VERSION ""

NS_ :

BS_:

BU_: XXX

BO_ 85 CID_RGHIGZ: 8 XXX
 SG_ sig_erymgc : 40|1@1+ (1,0) [0|1] "" XXX
 SG_ sig_tabrsm : 56|8@1+ (1,0) [0|255] "" XXX

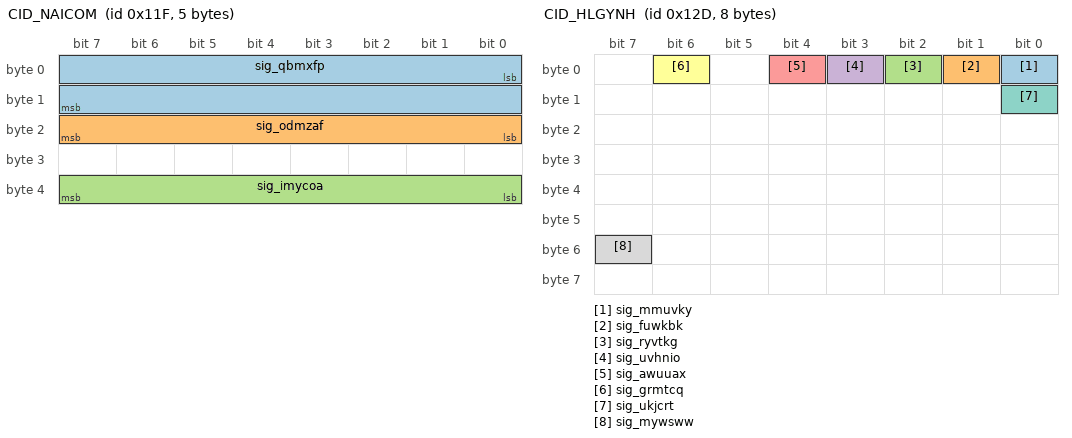
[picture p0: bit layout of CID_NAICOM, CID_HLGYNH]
BO_ 287 CID_NAICOM: 5 XXX
 SG_ sig_qbmxfp : 0|16@1- (0.1,0) [-450|450] "" XXX
 SG_ sig_odmzaf : 16|8@1+ (4,0) [0|1020] "" XXX
 SG_ sig_imycoa : 32|8@1+ (1,0) [0|255] "" XXX

BO_ 289 CID_RRNNRT: 8 XXX
 SG_ sig_yvbsvs : 0|12@1+ (1,0) [0|255] "" XXX

BO_ 301 CID_HLGYNH: 8 XXX
 SG_ sig_mmuvky : 0|1@0+ (1,0) [0|1] "" XXX
 SG_ sig_fuwkbk : 1|1@0+ (1,0) [0|1] "" XXX
 SG_ sig_ryvtkg : 2|1@0+ (1,0) [0|1] "" XXX
 SG_ sig_uvhnio : 3|1@0+ (1,0) [0|1] "" XXX
 SG_ sig_awuuax : 4|1@0+ (1,0) [0|1] "" XXX
 SG_ sig_grmtcq : 6|1@0+ (1,0) [0|1] "" XXX
 SG_ sig_ukjcrt : 8|1@0+ (1,0) [0|1] "" XXX
 SG_ sig_mywsww : 55|1@0+ (1,0) [0|1] "" XXX

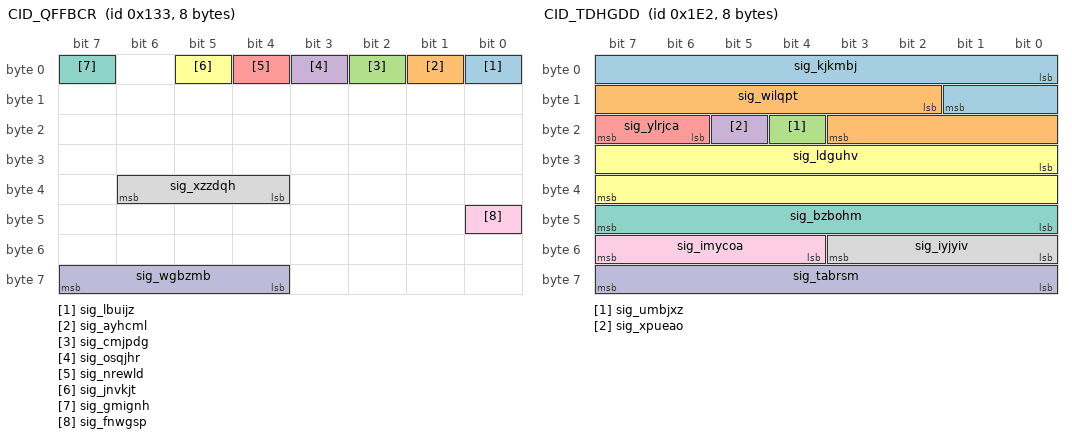
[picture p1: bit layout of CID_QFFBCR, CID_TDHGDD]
BO_ 307 CID_QFFBCR: 8 XXX
 SG_ sig_lbuijz : 0|1@0+ (1,0) [0|1] "" XXX
 SG_ sig_ayhcml : 1|1@1+ (1,0) [0|1] "" XXX
 SG_ sig_cmjpdg : 2|1@1+ (1,0) [0|1] "" XXX
 SG_ sig_osqjhr : 3|1@1+ (1,0) [0|1] "" XXX
 SG_ sig_nrewld : 4|1@0+ (1,0) [0|1] "" XXX
 SG_ sig_jnvkjt : 5|1@0+ (1,0) [0|1] "" XXX
 SG_ sig_gmignh : 7|1@0+ (1,0) [0|1] "" XXX
 SG_ sig_xzzdqh : 36|3@1+ (1,0) [0|7] "" XXX
 SG_ sig_fnwgsp : 40|1@0+ (1,0) [0|1] "" XXX
 SG_ sig_wgbzmb : 63|4@0+ (1,0) [0|15] "" XXX

BO_ 482 CID_TDHGDD: 8 XXX
 SG_ sig_kjkmbj : 0|10@1- (0.01,0) [0|5] "" XXX
 SG_ sig_wilqpt : 10|10@1- (0.01,0) [-5|0] "" XXX
 SG_ sig_umbjxz : 20|1@0+ (1,0) [0|1] "" XXX
 SG_ sig_xpueao : 21|1@0+ (1,0) [0|1] "" XXX
 SG_ sig_ylrjca : 22|2@1+ (1,0) [0|1] "" XXX
 SG_ sig_ldguhv : 24|16@1- (0.1,0) [-780|779.9] "" XXX
 SG_ sig_bzbohm : 47|8@0+ (1,0) [0|255] "" XXX
 SG_ sig_iyjyiv : 48|4@1+ (1,0) [0|15] "" XXX
 SG_ sig_imycoa : 52|4@1+ (1,0) [0|15] "" XXX
 SG_ sig_tabrsm : 56|8@1+ (1,0) [0|255] "" XXX

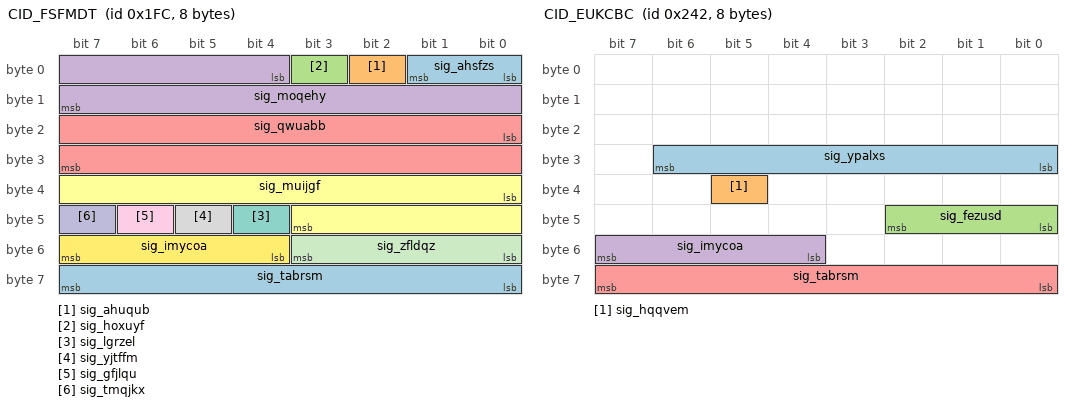
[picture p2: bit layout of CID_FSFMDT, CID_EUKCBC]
BO_ 508 CID_FSFMDT: 8 XXX
 SG_ sig_ahsfzs : 0|2@1+ (1,0) [0|1] "" XXX
 SG_ sig_ahuqub : 2|1@1+ (1,0) [0|1] "" XXX
 SG_ sig_hoxuyf : 3|1@0+ (1,0) [0|1] "" XXX
 SG_ sig_moqehy : 4|12@1- (1,0) [-2048|2047] "" XXX
 SG_ sig_qwuabb : 16|16@1- (0.1,0) [-780|779.9] "Deg" XXX
 SG_ sig_muijgf : 32|12@1- (1,0) [0|63] "" XXX
 SG_ sig_lgrzel : 44|1@0+ (1,0) [0|1] "" XXX
 SG_ sig_yjtffm : 45|1@1+ (1,0) [0|255] "" XXX
 SG_ sig_gfjlqu : 46|1@1+ (1,0) [0|1] "" XXX
 SG_ sig_tmqjkx : 47|1@0+ (1,0) [0|3] "" XXX
 SG_ sig_zfldqz : 48|4@1+ (1,0) [0|15] "" XXX
 SG_ sig_imycoa : 52|4@1+ (1,0) [0|15] "" XXX
 SG_ sig_tabrsm : 56|8@1+ (1,0) [0|255] "" XXX

BO_ 578 CID_EUKCBC: 8 XXX
 SG_ sig_ypalxs : 30|7@0+ (1,0) [0|127] "" XXX
 SG_ sig_hqqvem : 37|1@0+ (1,0) [0|1] "" XXX
 SG_ sig_fezusd : 40|3@1+ (1,0) [0|7] "" XXX
 SG_ sig_imycoa : 55|4@0+ (1,0) [0|15] "" XXX
 SG_ sig_tabrsm : 56|8@1+ (1,0) [0|255] "" XXX

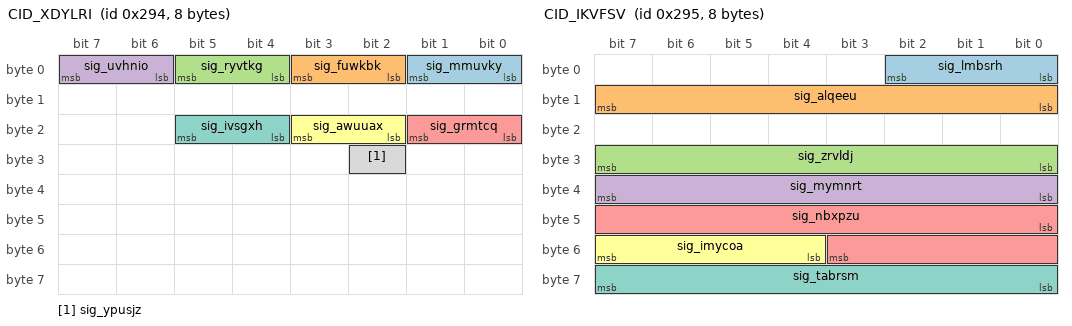
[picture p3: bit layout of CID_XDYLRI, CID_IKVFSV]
BO_ 660 CID_XDYLRI: 8 XXX
 SG_ sig_mmuvky : 1|2@0+ (1,0) [0|3] "" XXX
 SG_ sig_fuwkbk : 3|2@0+ (1,0) [0|3] "" XXX
 SG_ sig_ryvtkg : 5|2@0+ (1,0) [0|3] "" XXX
 SG_ sig_uvhnio : 7|2@0+ (1,0) [0|3] "" XXX
 SG_ sig_grmtcq : 17|2@0+ (1,0) [0|3] "" XXX
 SG_ sig_awuuax : 19|2@0+ (1,0) [0|3] "" XXX
 SG_ sig_ivsgxh : 21|2@0+ (1,0) [0|3] "" XXX
 SG_ sig_ypusjz : 26|1@0+ (1,0) [0|1] "" XXX

BO_ 661 CID_IKVFSV: 8 XXX
 SG_ sig_lmbsrh : 2|3@0+ (1,0) [0|7] "" XXX
 SG_ sig_alqeeu : 15|8@0+ (1,0) [0|255] "" XXX
 SG_ sig_zrvldj : 31|8@0+ (1,0) [0|255] "" XXX
 SG_ sig_mymnrt : 32|8@1+ (1,0) [0|255] "" XXX
 SG_ sig_nbxpzu : 40|12@1+ (1,0) [0|255] "" XXX
 SG_ sig_imycoa : 52|4@1+ (1,0) [0|15] "" XXX
 SG_ sig_tabrsm : 63|8@0+ (1,0) [0|255] "" XXX

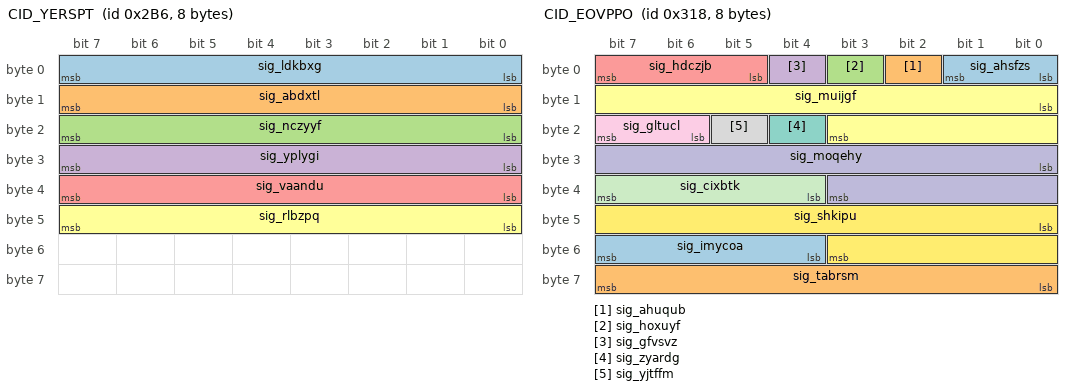
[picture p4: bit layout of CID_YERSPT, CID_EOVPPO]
BO_ 694 CID_YERSPT: 8 XXX
 SG_ sig_ldkbxg : 7|8@0+ (1,0) [0|255] "" XXX
 SG_ sig_abdxtl : 15|8@0+ (1,0) [0|255] "" XXX
 SG_ sig_nczyyf : 23|8@0+ (1,0) [0|255] "" XXX
 SG_ sig_yplygi : 31|8@0+ (1,0) [0|255] "" XXX
 SG_ sig_vaandu : 39|8@0+ (1,0) [0|255] "" XXX
 SG_ sig_rlbzpq : 47|8@0+ (1,0) [0|255] "" XXX

BO_ 790 CID_DWCEKH: 8 XXX
 SG_ sig_htfsoi : 3|4@0+ (1,0) [0|1] "" XXX
 SG_ sig_jocmxa : 4|2@1+ (1,0) [0|3] "" XXX
 SG_ sig_burihc : 6|2@1+ (1,0) [0|3] "" XXX
 SG_ sig_hjivba : 8|2@1+ (1,0) [0|3] "" XXX
 SG_ sig_hfdwhw : 10|1@1+ (1,0) [0|1] "" XXX
 SG_ sig_kehpna : 11|4@1+ (1,0) [0|1] "" XXX
 SG_ sig_dbgurt : 15|1@0+ (1,0) [0|1] "" XXX
 SG_ sig_ldguhv : 16|11@1- (1,0) [-1024|1023] "" XXX
 SG_ sig_umbjxz : 27|1@1+ (1,0) [0|1] "" XXX
 SG_ sig_xpueao : 28|1@1+ (1,0) [0|3] "" XXX
 SG_ sig_omzumr : 29|1@0+ (1,0) [0|1] "" XXX
 SG_ sig_ssdpae : 30|1@0+ (1,0) [0|1] "" XXX
 SG_ sig_sbkelk : 31|1@0+ (1,0) [0|1] "" XXX
 SG_ sig_qvymsq : 32|2@1+ (1,0) [0|3] "" XXX
 SG_ sig_fttojk : 34|2@1+ (1,0) [0|3] "" XXX
 SG_ sig_uhpulr : 36|4@1+ (1,0) [0|3] "" XXX
 SG_ sig_nwzzgs : 40|8@1+ (5,-5) [-5|1270] "" XXX
 SG_ sig_durxgl : 49|2@0+ (1,0) [0|3] "" XXX
 SG_ sig_hzwiax : 51|2@0+ (1,0) [0|3] "" XXX
 SG_ sig_imycoa : 52|4@1+ (1,0) [0|15] "" XXX
 SG_ sig_tabrsm : 56|8@1+ (1,0) [0|15] "" XXX

BO_ 792 CID_EOVPPO: 8 XXX
 SG_ sig_ahsfzs : 0|2@1+ (1,0) [0|1] "" XXX
 SG_ sig_ahuqub : 2|1@1+ (1,0) [0|1] "" XXX
 SG_ sig_hoxuyf : 3|1@1+ (1,0) [0|1] "" XXX
 SG_ sig_gfvsvz : 4|1@1+ (1,0) [0|1] "" XXX
 SG_ sig_hdczjb : 5|3@1+ (1,0) [0|1] "" XXX
 SG_ sig_muijgf : 8|12@1- (1,0) [-2048|2047] "" XXX
 SG_ sig_zyardg : 20|1@1+ (1,0) [0|1] "" XXX
 SG_ sig_yjtffm : 21|1@1+ (1,0) [0|1] "" XXX
 SG_ sig_gltucl : 22|2@1+ (1,0) [0|15] "" XXX
 SG_ sig_moqehy : 24|12@1- (1,0) [-2048|2047] "" XXX
 SG_ sig_cixbtk : 36|4@1+ (1,0) [0|15] "" XXX
 SG_ sig_shkipu : 40|12@1+ (1,0) [0|4095] "" XXX
 SG_ sig_imycoa : 52|4@1+ (1,0) [0|15] "" XXX
 SG_ sig_tabrsm : 56|8@1+ (1,0) [0|255] "" XXX

BO_ 813 CID_ZSMXVI: 8 XXX
 SG_ sig_dtgmtn : 0|9@1+ (0.5,0) [0|255.5] "" XXX
 SG_ sig_dfduvu : 9|1@1+ (1,0) [0|1] "" XXX
 SG_ sig_tfxgwz : 10|3@1+ (1,0) [0|7] "" XXX
 SG_ sig_audjry : 13|3@1+ (1,0) [0|7] "" XXX
 SG_ sig_iemtek : 16|1@1+ (1,0) [0|1] "" XXX
 SG_ sig_jfxrrg : 17|1@1+ (1,0) [0|1] "" XXX
 SG_ sig_hoxuyf : 18|1@1+ (1,0) [0|1] "" XXX
 SG_ sig_wenixj : 19|3@1+ (1,0) [0|1] "" XXX
 SG_ sig_kyxjpd : 22|1@0+ (1,0) [0|1] "" XXX
 SG_ sig_aabhqk : 23|1@0+ (1,0) [0|1] "" XXX
 SG_ sig_hjivba : 24|1@1+ (1,0) [0|1] "" XXX
 SG_ sig_uvuplq : 25|7@1+ (1,0) [0|127] "" XXX
 SG_ sig_niryjk : 32|4@1+ (1,0) [0|15] "" XXX
 SG_ sig_ywmmum : 36|12@1+ (1,0) [0|4095] "" XXX
 SG_ sig_imycoa : 48|4@1+ (1,0) [0|15] "" XXX
 SG_ sig_vkxjds : 55|4@0+ (1,0) [0|15] "" XXX
 SG_ sig_tabrsm : 56|8@1+ (1,0) [0|255] "" XXX

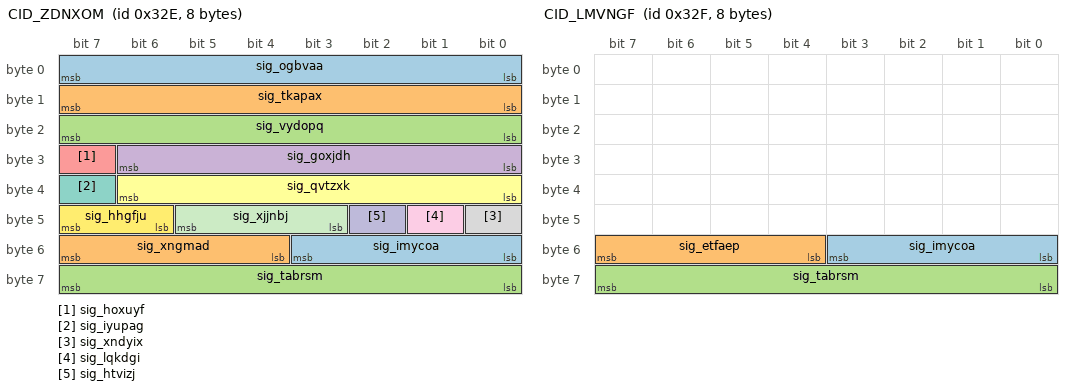
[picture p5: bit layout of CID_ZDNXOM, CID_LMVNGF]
BO_ 814 CID_ZDNXOM: 8 XXX
 SG_ sig_ogbvaa : 0|8@1+ (0.05,-5) [-100|155] "" XXX
 SG_ sig_tkapax : 8|8@1+ (0.05,-5) [0|1.26] "" XXX
 SG_ sig_vydopq : 16|8@1+ (0.05,-5) [0|1.26] "" XXX
 SG_ sig_goxjdh : 24|7@1+ (0.2,0) [0|12.7] "" XXX
 SG_ sig_hoxuyf : 31|1@0+ (1,0) [0|1] "" XXX
 SG_ sig_qvtzxk : 32|7@1+ (0.2,-16) [0|12.7] "" XXX
 SG_ sig_iyupag : 39|1@0+ (1,0) [0|1] "" XXX
 SG_ sig_xndyix : 40|1@0+ (1,0) [0|1] "" XXX
 SG_ sig_lqkdgi : 41|1@0+ (1,0) [0|1] "" XXX
 SG_ sig_htvizj : 42|1@1+ (1,0) [0|3] "" XXX
 SG_ sig_xjjnbj : 45|3@0+ (1,0) [0|1] "" XXX
 SG_ sig_hhgfju : 46|2@1+ (1,0) [0|3] "" XXX
 SG_ sig_imycoa : 48|4@1+ (1,0) [0|15] "" XXX
 SG_ sig_xngmad : 55|4@0+ (1,0) [0|15] "" XXX
 SG_ sig_tabrsm : 56|8@1+ (1,0) [0|255] "" XXX

BO_ 815 CID_LMVNGF: 8 XXX
 SG_ sig_imycoa : 48|4@1+ (1,0) [0|15] "" XXX
 SG_ sig_etfaep : 55|4@0+ (1,0) [0|15] "" XXX
 SG_ sig_tabrsm : 56|8@1+ (1,0) [0|255] "" XXX

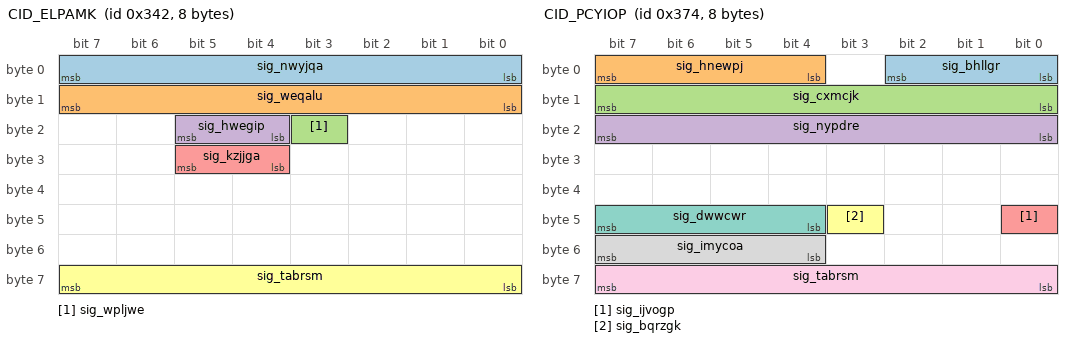
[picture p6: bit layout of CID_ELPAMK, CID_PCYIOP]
BO_ 834 CID_ELPAMK: 8 XXX
 SG_ sig_nwyjqa : 0|8@1+ (0.01,0) [0|2.55] "" XXX
 SG_ sig_weqalu : 8|8@1+ (0.01,0) [0|2.55] "" XXX
 SG_ sig_wpljwe : 19|1@1+ (1,0) [0|1] "" XXX
 SG_ sig_hwegip : 20|2@1+ (1,0) [0|255] "" XXX
 SG_ sig_kzjjga : 28|2@1+ (1,0) [0|1] "" XXX
 SG_ sig_tabrsm : 56|8@1+ (1,0) [0|255] "" XXX

BO_ 884 CID_PCYIOP: 8 MRR
 SG_ sig_bhllgr : 2|3@0+ (1,0) [0|3] "" MRR
 SG_ sig_hnewpj : 7|4@0+ (1,0) [0|15] "" MRR
 SG_ sig_cxmcjk : 15|8@0+ (0.1,-12) [0|255] "" MRR
 SG_ sig_nypdre : 23|8@0+ (1,-100) [0|255] "" MRR
 SG_ sig_ijvogp : 40|1@0+ (1,0) [0|3] "" MRR
 SG_ sig_bqrzgk : 43|1@0+ (1,0) [0|1] "" XXX
 SG_ sig_dwwcwr : 44|4@1+ (1,0) [0|15] "" XXX
 SG_ sig_imycoa : 52|4@1+ (1,0) [0|15] "" MRR
 SG_ sig_tabrsm : 56|8@1+ (1,0) [0|255] "" MRR

BO_ 944 CID_FCANVE: 8 XXX
 SG_ sig_qtdxxb : 1|2@0+ (1,0) [0|3] "" XXX
 SG_ sig_inouau : 2|1@0+ (1,0) [0|1] "" XXX
 SG_ sig_swtewx : 4|2@0+ (1,0) [0|3] "" XXX
 SG_ sig_abolan : 5|1@0+ (1,0) [0|1] "" XXX
 SG_ sig_uwgtyj : 6|1@0+ (1,0) [0|1] "" XXX
 SG_ sig_jcpbxn : 7|1@0+ (1,0) [0|1] "" XXX
 SG_ sig_aduutq : 8|1@0+ (1,0) [0|1] "" XXX
 SG_ sig_vmhefm : 11|3@0+ (1,0) [0|7] "" XXX
 SG_ sig_eryicw : 12|1@0+ (1,0) [0|1] "" XXX
 SG_ sig_qtpkbx : 14|2@0+ (1,0) [0|3] "" XXX
 SG_ sig_esppdh : 15|1@0+ (1,0) [0|1] "" XXX
 SG_ sig_lwodux : 16|1@0+ (1,0) [0|1] "" XXX
 SG_ sig_onjnau : 18|2@0+ (1,0) [0|3] "" XXX
 SG_ sig_geqmml : 19|1@0+ (1,0) [0|1] "" XXX
 SG_ sig_ygzest : 23|4@0+ (1,0) [0|15] "" XXX
 SG_ sig_lxkshl : 24|28@1+ (1,0) [0|268435455] "" XXX
 SG_ sig_imycoa : 52|4@1+ (1,0) [0|15] "" XXX
 SG_ sig_tabrsm : 56|8@1+ (1,0) [0|255] "" XXX

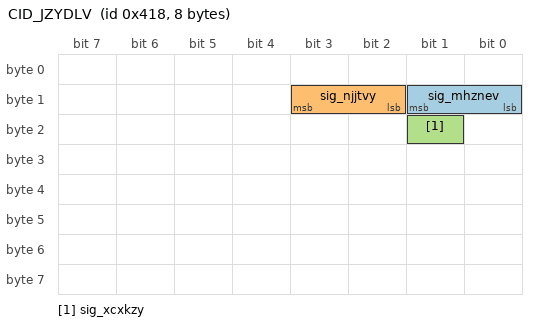
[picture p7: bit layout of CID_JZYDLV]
BO_ 1048 CID_JZYDLV: 8 XXX
 SG_ sig_mhznev : 9|2@0+ (1,0) [0|1] "" XXX
 SG_ sig_njjtvy : 11|2@0+ (1,0) [0|1] "" XXX
 SG_ sig_xcxkzy : 17|1@0+ (1,0) [0|1] "" XXX

VAL_ 578 sig_fezusd 4 "D" 2 "R" 3 "N" 1 "P";
VAL_ 790 sig_htfsoi 11 "AutoFullBeamActive" 2 "AutoFullBeamInactive";
VAL_ 790 sig_jocmxa 0 "GRAY" 1 "GREEN" 2 "YELLOW" 3 "RED";
VAL_ 790 sig_burihc 3 "ALARM_AND_LKA" 2 "LKA" 1 "ALARM" 0 "DISABLE";
VAL_ 790 sig_fttojk 0 "GRAY" 1 "GREEN" 2 "YELLOW" 3 "RED";
VAL_ 790 sig_durxgl 0 "VIBRATION" 1 "AUDIO" 2 "AUDIO_AND_VIBRATION";
VAL_ 792 sig_ahsfzs 0 "NotReady" 1 "Ready" 2 "Active" 3 "TemporaryFail";
VAL_ 813 sig_tfxgwz 4 "4BAR" 3 "3BAR" 2 "2BAR" 1 "1BAR";
VAL_ 813 sig_wenixj 0 "OFF" 2 "ACC_ON" 3 "ACC_ACTIVE" 5 "FORCE_ACCEL" 7 "ERROR";
VAL_ 813 sig_uvuplq 36 "ACC_ERROR" 22 "OVERRIDE" 12 "ENGAGE" 8 "DISENGAGE" 20 "ACC_ON" 32 "ACC_OFF" 48 "CHECK_GEAR_D" 16 "FORCE_ACCEL" 0 "NONE";
VAL_ 814 sig_xjjnbj 0 "Off" 1 "Passive" 2 "StandBy" 3 "ActiveControl" 4 "BrakeOnly" 5 "Override" 6 "Standstill" 7 "Failure";
VAL_ 814 sig_hhgfju 0 "Softoff" 1 "Fastoff" 2 "Immediateoff" 3 "Initial";
VAL_ 834 sig_hwegip 2 "SPORT" 1 "ECO" 0 "SNOW";
VAL_ 834 sig_kzjjga 3 "HEV" 2 "FORCE_EV" 1 "EV";
VAL_ 944 sig_swtewx 0 "NOTPRESSED" 1 "DOWN_SETSPEED" 3 "UP_RESETSPEED";
